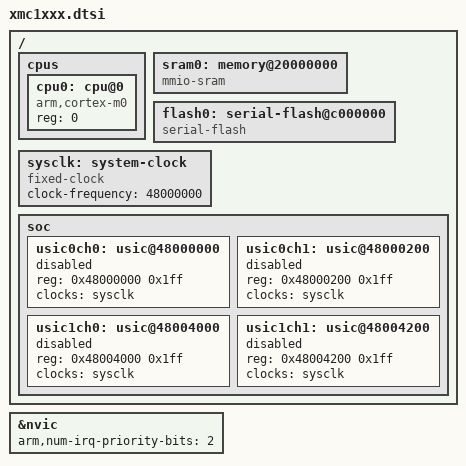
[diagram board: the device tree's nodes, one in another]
/*
 * Copyright (c) 2021 Linumiz
 * Author: Parthiban Nallathambi <parthiban@linumiz.com>
 *
 * SPDX-License-Identifier: Apache-2.0
 */

#include <arm/armv7-m.dtsi>

/ {
	cpus {
		#address-cells = <1>;
		#size-cells = <0>;

		cpu0: cpu@0 {
			compatible = "arm,cortex-m0";
			reg = <0>;
		};
	};

	sram0: memory@20000000 {
		compatible = "mmio-sram";
	};

	flash0: serial-flash@c000000 {
		compatible = "serial-flash";
	};

	sysclk: system-clock {
		compatible = "fixed-clock";
		clock-frequency = <48000000>;
		#clock-cells = <0>;
	};

	soc {
		usic0ch0: usic@48000000 {
			reg = <0x48000000 0x1ff>;
			clocks = <&sysclk>;
			status = "disabled";
		};

		usic0ch1: usic@48000200 {
			reg = <0x48000200 0x1ff>;
			clocks = <&sysclk>;
			status = "disabled";
		};

		usic1ch0: usic@48004000 {
			reg = <0x48004000 0x1ff>;
			clocks = <&sysclk>;
			status = "disabled";
		};

		usic1ch1: usic@48004200 {
			reg = <0x48004200 0x1ff>;
			clocks = <&sysclk>;
			status = "disabled";
		};
	};
};

&nvic {
	arm,num-irq-priority-bits = <2>;
};
